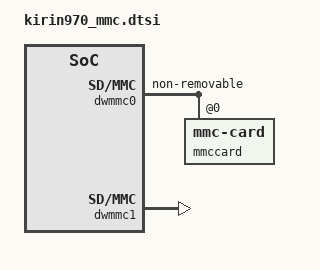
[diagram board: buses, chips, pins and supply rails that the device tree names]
/{
	aliases {
		mshc0 = &dwmmc0;
		mshc1 = &dwmmc1;
		/*mshc2 = &dwmmc2;*/
	};

	/* emmc 4.5 */
	dwmmc0: dwmmc0@FC183000 {
		compatible = "hisilicon,kirin970-dw-mshc";
		reg = <0x0 0xfc183000 0x0 0x1000>;
		interrupts = <0 140 4>;
		clocks = <&clk_gate_sdio>, <&hclk_gate_sdio>;
		clock-names = "ciu", "biu";
		interrupt-parent = <&gic>;
		num-slots = <1>;
		fifo-depth = <0x100>;
		card-detect-delay = <200>;
		broken-cd;
		non-removable;
		supports-highspeed;
		/*caps2-mmc-packed-command;*/
		caps2-mmc-hs200-1_8v;
		caps2-mmc-cache-ctrl;
		/*caps2-mmc-poweroff-notify;*/
		pinctrl-names = "default", "idle";
		pinctrl-0 = <&gpio128_pmx_func &gpio129_pmx_func &gpio130_pmx_func
				&gpio131_pmx_func &gpio132_pmx_func &gpio133_pmx_func
				&gpio134_pmx_func &gpio135_pmx_func &gpio136_pmx_func
				&gpio137_pmx_func &gpio128_cfg_func &gpio129_cfg_func
				&gpio130_cfg_func &gpio131_cfg_func &gpio132_cfg_func
				&gpio133_cfg_func &gpio134_cfg_func &gpio135_cfg_func
				&gpio136_cfg_func &gpio137_cfg_func>;
		pinctrl-1 = <&gpio128_pmx_idle &gpio129_pmx_idle &gpio130_pmx_idle
				&gpio131_pmx_idle &gpio132_pmx_idle &gpio133_pmx_idle
				&gpio134_pmx_idle &gpio135_pmx_idle &gpio136_pmx_idle
				&gpio137_pmx_idle &gpio128_cfg_idle &gpio129_cfg_idle
				&gpio130_cfg_idle &gpio131_cfg_idle &gpio132_cfg_idle
				&gpio133_cfg_idle &gpio134_cfg_idle &gpio135_cfg_idle
				&gpio136_cfg_idle &gpio137_cfg_idle>;
		status = "ok";
		slot@0 {
			reg = <0>;
			bus-width = <8>;
			disable-wp;
		};

		mmccard: mmccard@0 {
			reg = <0>;
			compatible = "mmc-card";
			broken-hpi;
		};
	};

	/* SD */
	dwmmc1: dwmmc1@FF37F000 {
		compatible = "hisilicon,kirin970-dw-mshc";
		reg = <0x0 0xff37f000 0x0 0x1000>;
		interrupts = <0 139 4>;
		num-slots = <1>;
		clocks = <&clk_gate_sd>, <&hclk_gate_sd>;
		clock-names = "ciu", "biu";
		fifo-depth = <0x100>;
		card-detect-delay = <100>;
		supports-highspeed;
		debug_percrg_sd_sdio_reg_print = <0x1>;
		pinctrl-names = "default","idle";
		pinctrl-0 = <&gpio160_pmx_func &gpio161_pmx_func &gpio162_pmx_func
				&gpio163_pmx_func &gpio164_pmx_func &gpio165_pmx_func
				&gpio160_cfg_func &gpio161_cfg_func &gpio162_cfg_func
				&gpio163_cfg_func &gpio164_cfg_func &gpio165_cfg_func>;
		pinctrl-1 = <&gpio160_pmx_idle &gpio161_pmx_idle &gpio162_pmx_idle
				&gpio163_pmx_idle &gpio164_pmx_idle &gpio165_pmx_idle
				&gpio160_cfg_idle &gpio161_cfg_idle &gpio162_cfg_idle
				&gpio163_cfg_idle &gpio164_cfg_idle &gpio165_cfg_idle>;
		slot@0 {
                       reg = <0>;
                       bus-width = <4>;
                       disable-wp;
               };
	};

	/* wifi */
	/*
	dwmmc2: dwmmc2@FC183000 {
		compatible = "hisilicon,kirin970-dw-mshc";
		reg = <0x0 0xfc183000 0x0 0x1000>;
		interrupts = <0 140 4>;
		num-slots = <1>;
		clocks = <&clk_gate_sdio>, <&hclk_gate_sdio>;
		clock-names = "ciu", "biu";
		fifo-depth = <0x100>;
		card-detect-delay = <200>;
		caps2-support-wifi;
		supports-highspeed;
		keep-power-in-suspend;
		pinctrl-names = "default","idle";
		pinctrl-0 = <>;
		pinctrl-1 = <>;
		slot@0 {
			reg = <0>;
			bus-width = <4>;
			disable-wp;
		};
	};
	*/
};
